# NUC123AE_v1 register map
File version: 1.0
Registers are 32-bit, read-write, reset 0x0 unless marked. A register's access mark holds for its fields unless they carry their own. Offsets are from the block's base; [hi:lo] are bit positions; {n}, {i} and the like mark numbered series.

## FMC — FMC Register Map
Base 0x5000C000
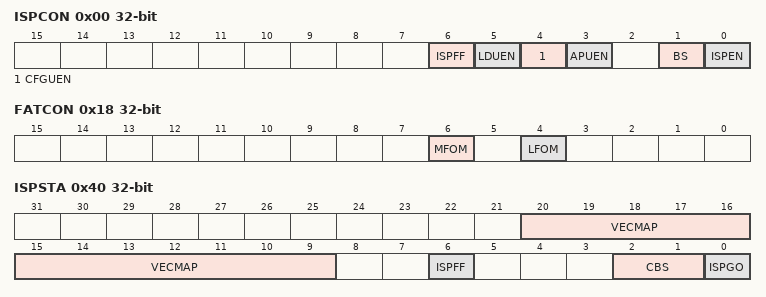
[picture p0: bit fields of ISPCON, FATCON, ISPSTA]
0x00 ISPCON — ISP Control Register
  [6] ISPFF — ISP Fail Flag (Write-protection Bit). This bit is set by hardware when a triggered ISP meets any of the following conditions: (1) APROM writes to itself if APUEN is set to 0. (2) LDROM writes to itself if LDUEN is set to 0. (3) CONFIG is erased/programmed if CFGUEN is set to 0. (4) Destination address is illegal, such as over an available range. Write 1 to clear.
  [5] LDUEN — LDROM Update Enable (Write-protection Bit). LDROM update enable bit.
    0=LDROM cannot be updated; 1=LDROM can be updated
  [4] CFGUEN — Enable Config-bits Update by ISP (Write-protection Bit)
    0=ISP Disabled to update config-bits; 1=ISP Enabled to update config-bits
  [3] APUEN — APROM Update Enable (Write-protection Bit)
    0=APROM cannot be updated when the chip runs in APROM; 1=APROM can be updated when the chip runs in APROM
  [1] BS — Boot Select (Write-protection Bit). Set/clear this bit to select next booting from LDROM/APROM, respectively. This bit also functions as chip booting status flag, which can be used to check where chip booted from. This bit is initiated with the inversed value of CBS in Config0 after any reset is happened except CPU reset (RSTS_CPU is 1) or system reset (RSTS_SYS) is happened
    0=Boot from APROM; 1=Boot from LDROM
  [0] ISPEN — ISP Enable (Write-protection Bit). ISP function enable bit. Set this bit to enable ISP function.
    0=ISP function Disabled; 1=ISP function Enabled
0x04 ISPADR — ISP Address Register
  [31:0] ISPADR — ISP Address. The NuMicro( NUC123 Series is equipped with an embedded flash, and it supports word program only. ISPADR[1:0] must be kept 00b for ISP operation.
0x08 ISPDAT — ISP Data Register
  [31:0] ISPDAT — ISP Data. Write data to this register before ISP program operation. Read data from this register after ISP read operation.
0x0C ISPCMD — ISP Command Register
  [5:0] ISPCMD — ISP Command
0x10 ISPTRG — ISP Trigger Control Register
  [0] ISPGO — ISP Start Trigger. Write 1 to start ISP operation and this bit will be cleared to 0 by hardware automatically when ISP operation is finished.
    0=ISP operation is finished; 1=ISP is progressed
0x14 DFBADR ro reset 0x1F000 — Data Flash Base Address Register
  [31:0] DFBADR — Data Flash Base Address. This register indicates data flash start address. It is a read only register. When DFVSEN is set to 0, the data flash is shared with APROM. The data flash size is defined by user configuration and the content of this register is loaded from Config1. When DFVSEN is set to 1, the data flash size is fixed as 4K and the start address can be read from this register is fixed at 0x0001_F000.
0x18 FATCON — Flash Access Time Control Register
  [6] MFOM — Middle Frequency Optimization Mode (Write-protection Bit). When chip operation frequency is lower than 50 MHz, chip can work more efficiently by setting this bit to 1
    0=Middle Frequency Optimization mode Disabled; 1=Middle Frequency Optimization mode Enabled
  [4] LFOM — Low Frequency Optimization Mode (Write-protection Bit). When chip operation frequency is lower than 25 MHz, chip can work more efficiently by setting this bit to 1
    0=Low Frequency Optimization mode Disabled; 1=Low Frequency Optimization mode Enabled
0x40 ISPSTA — ISP Status Register
  [20:9] VECMAP ro — Vector Page Mapping Address (Read only). The current flash address space 0x0000_0000~0x0000_01FF is mapping to address {VECMAP[11:0], 9'h000} ~ {VECMAP[11:0], 9'h1FF}
  [6] ISPFF — ISP Fail Flag (Write-protection Bit). This bit is set by hardware when a triggered ISP meets any of the following conditions: (1) APROM writes to itself. (2) LDROM writes to itself. (3) CONFIG is erased/programmed if CFGUEN is set to 0. (4) Destination address is illegal, such as over an available range. Write 1 to clear. Note: This bit functions the same as ISPCON bit 6.
  [2:1] CBS ro — Config Boot Selection (Read only)
  [0] ISPGO ro — ISP Start Trigger (Read only). Write 1 to start ISP operation and this bit will be cleared to 0 by hardware automatically when ISP operation is finished. Note: This bit is the same with ISPTRG bit 0.
    0=ISP operation is finished; 1=ISP is progressed
